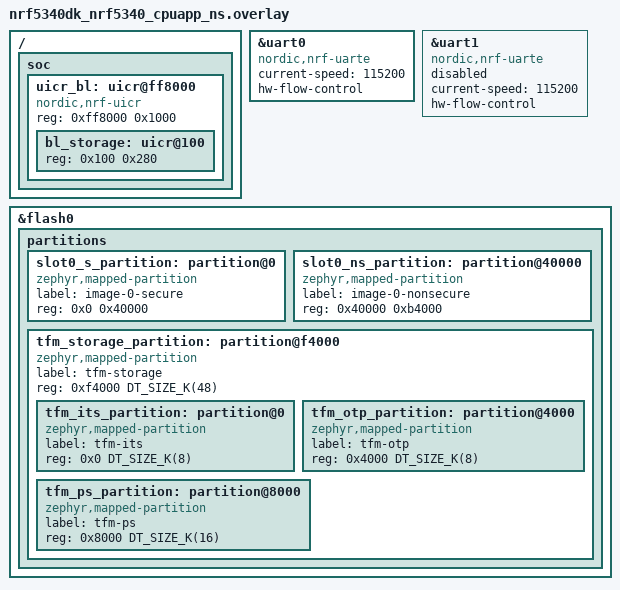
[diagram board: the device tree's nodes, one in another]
/*
 * Copyright (c) 2024 Nordic Semiconductor ASA
 *
 * SPDX-License-Identifier: LicenseRef-Nordic-5-Clause
 */
&uart0 {
	compatible = "nordic,nrf-uarte";
	current-speed = <115200>;
	status = "okay";
	hw-flow-control;
};

&uart1 {
	compatible = "nordic,nrf-uarte";
	current-speed = <115200>;
	/* Set to disabled in application, since TF-M will be using it. */
	status = "disabled";
	hw-flow-control;
};

/delete-node/ &boot_partition;
/delete-node/ &slot0_partition;
/delete-node/ &slot1_partition;
/delete-node/ &tfm_ps_partition;
/delete-node/ &tfm_its_partition;
/delete-node/ &tfm_otp_partition;
/delete-node/ &storage_partition;

/* Resolve bl_storage in the forwarded TF-M secure image. */
/ {
	soc {
		uicr_bl: uicr@ff8000 {
			compatible = "nordic,nrf-uicr";
			reg = <0xff8000 0x1000>;
			ranges = <0x0 0xff8000 0x1000>;
			#address-cells = <1>;
			#size-cells = <1>;

			bl_storage: uicr@100 {
				reg = <0x100 0x280>;
			};
		};
	};
};

&flash0 {
	partitions {
		slot0_s_partition: partition@0 {
			compatible = "zephyr,mapped-partition";
			label = "image-0-secure";
			reg = <0x0 0x40000>;
		};

		slot0_ns_partition: partition@40000 {
			compatible = "zephyr,mapped-partition";
			label = "image-0-nonsecure";
			reg = <0x40000 0xb4000>;
		};

		tfm_storage_partition: partition@f4000 {
			compatible = "zephyr,mapped-partition";
			label = "tfm-storage";
			reg = <0xf4000 DT_SIZE_K(48)>;
			ranges = <0x0 0xf4000 DT_SIZE_K(48)>;
			#address-cells = <1>;
			#size-cells = <1>;

			tfm_its_partition: partition@0 {
				compatible = "zephyr,mapped-partition";
				label = "tfm-its";
				reg = <0x0 DT_SIZE_K(8)>;
			};

			tfm_otp_partition: partition@4000 {
				compatible = "zephyr,mapped-partition";
				label = "tfm-otp";
				reg = <0x4000 DT_SIZE_K(8)>;
			};

			tfm_ps_partition: partition@8000 {
				compatible = "zephyr,mapped-partition";
				label = "tfm-ps";
				reg = <0x8000 DT_SIZE_K(16)>;
			};
		};
	};
};
